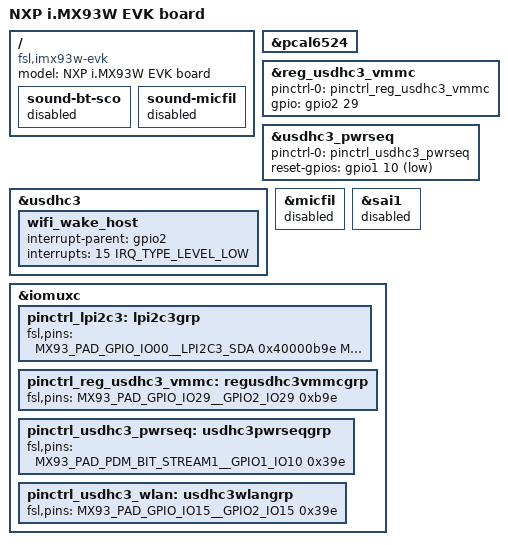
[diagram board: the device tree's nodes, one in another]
// SPDX-License-Identifier: (GPL-2.0+ OR MIT)
/*
 * Copyright 2025 NXP
 */

#include "imx93-11x11-evk.dts"

/ {
	model = "NXP i.MX93W EVK board";
	compatible = "fsl,imx93w-evk", "fsl,imx93";

	/delete-node/ regulator-m2-pwr;

	sound-bt-sco {
		status = "disabled";
	};

	sound-micfil {
		status = "disabled";
	};
};

&pcal6524 {
	/delete-node/ m2-pcm-level-shifter-hog;
};

&reg_usdhc3_vmmc {
	/delete-property/ vin-supply;
	pinctrl-0 = <&pinctrl_reg_usdhc3_vmmc>;
	pinctrl-names = "default";
	gpio = <&gpio2 29 GPIO_ACTIVE_HIGH>;
};

&usdhc3_pwrseq {
	pinctrl-0 = <&pinctrl_usdhc3_pwrseq>;
	pinctrl-names = "default";
	reset-gpios = <&gpio1 10 GPIO_ACTIVE_LOW>;
};

&usdhc3 {
	wifi_wake_host {
		interrupt-parent = <&gpio2>;
		interrupts = <15 IRQ_TYPE_LEVEL_LOW>;
	};
};

&micfil {
	status = "disabled";
};

&sai1 {
	status = "disabled";
};

&iomuxc {
	pinctrl_lpi2c3: lpi2c3grp {
		fsl,pins = <
			MX93_PAD_GPIO_IO00__LPI2C3_SDA			0x40000b9e
			MX93_PAD_GPIO_IO01__LPI2C3_SCL			0x40000b9e
		>;
	};

	pinctrl_reg_usdhc3_vmmc: regusdhc3vmmcgrp {
		fsl,pins = <
			/*
			 * Enable open drain and internal pull-up to allow the IW610 JTAG
			 * connector to control the PDn status.
			 */
			MX93_PAD_GPIO_IO29__GPIO2_IO29			0xb9e
		>;
	};

	pinctrl_usdhc3_pwrseq: usdhc3pwrseqgrp {
		fsl,pins = <
			MX93_PAD_PDM_BIT_STREAM1__GPIO1_IO10		0x39e
		>;
	};

	pinctrl_usdhc3_wlan: usdhc3wlangrp {
		fsl,pins = <
			MX93_PAD_GPIO_IO15__GPIO2_IO15			0x39e
		>;
	};
};
